# AC7842x register map
Vendor: AutoChips; Series: AC78; File version: 1.0
CPU: CM4 r0p1, little endian, MPU, FPU, VTOR, 4 interrupt priority bits
Registers are 32-bit, read-write, reset 0x0 unless marked. A register's access mark holds for its fields unless they carry their own. Offsets are from the block's base; [hi:lo] are bit positions; {n}, {i} and the like mark numbered series; 'fields as' and 'values as' point back to an identical list.

## SPM — System Power Manage
Base 0x40008000
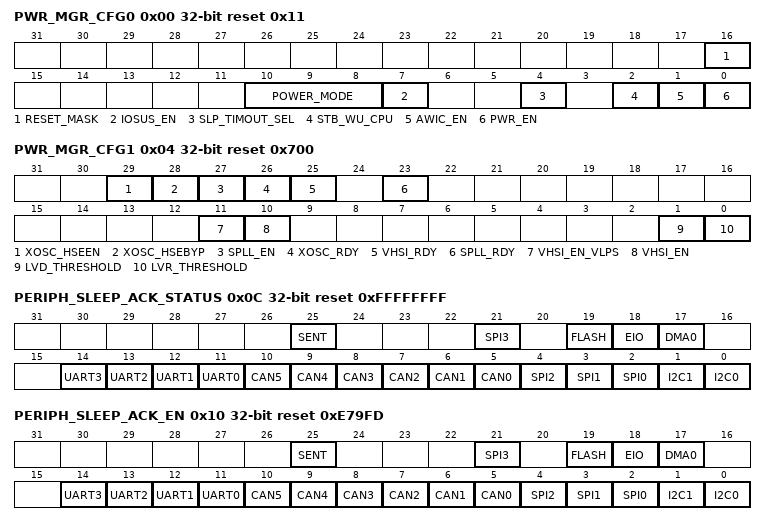
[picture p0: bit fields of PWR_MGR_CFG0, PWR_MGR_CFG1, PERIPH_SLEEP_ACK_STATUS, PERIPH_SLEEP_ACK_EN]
0x00 PWR_MGR_CFG0 reset 0x11 — Power Manage Config Register 0
  [16] RESET_MASK — Mask external reset in standby mode
    0=Disable; 1=Enable
  [10:8] POWER_MODE — Power Mode Control
    0=RUN Mode; 2=STOP1 Mode; 4=VLPS Mode; 5=Standby Mode
  [7] IOSUS_EN — IO suspend in low power mode
    0=Disable; 1=Enable
  [4] SLP_TIMOUT_SEL — Select SPM Interrupt/RESET When Occur ACK TimeOut
    0=Interrupt; 1=Reset
  [2] STB_WU_CPU — CPU continue run after standby wakeup
    0=Disable; 1=Enable
  [1] AWIC_EN — Enable AWIC Module
    0=Dsable; 1=Enable
  [0] PWR_EN — SPM Power Control Enable
    0=Disable; 1=Enable
0x04 PWR_MGR_CFG1 reset 0x700 — Power Manage Config Register 1
  [29] XOSC_HSEEN — Extern High-Speed Clock Enable
    0=Disable XOSC HSE; 1=Enable XOSC HSE
  [28] XOSC_HSEBYP — Extern High-Speed Clock Bypass
    0=Disable XOSC HSE Bypass; 1=Enable XOSC HSE Bypass
  [27] SPLL_EN — System PLL Enable
    0=Disable PLL; 1=Enable PLL
  [26] XOSC_RDY ro — XOSC Clock Ready Flag
    0=Not Ready; 1=Ready
  [25] VHSI_RDY ro — VHSI Ready Flag
    0=Not Ready; 1=Ready
  [23] SPLL_RDY ro — System PLL Ready Flag
    0=Not Ready; 1=Ready
  [11] VHSI_EN_VLPS — VHSI Enable in VLPS mode
    0=Disable; 1=Enable
  [10] VHSI_EN — VHSI Enable
    0=Disable; 1=Enable
  [1] LVD_THRESHOLD — LVD Voltage Threshold Set
    0=VLVDL=2.9V; 1=VLVDL=4.5V
  [0] LVR_THRESHOLD — LVR Voltage Threshold Set
    0=VLVRL=2.65V; 1=VLVRL=2.22V
0x0C PERIPH_SLEEP_ACK_STATUS ro reset 0xFFFFFFFF
  [25] SENT — SENT Sleep ACK Status
    0=No ACK; 1=ACK
  [21] SPI3 — SPI3 Sleep ACK Status
    0=No ACK; 1=ACK
  [19] FLASH — FLASH ACK Status
    0=NO ACK; 1=ACK
  [18] EIO — EIO Sleep ACK Status
    0=No ACK; 1=ACK
  [17] DMA0 — DMA0 Sleep ACK Status
    0=No ACK; 1=ACK
  [n+11] UART{n} (n=0..3) — UART{n} Sleep ACK Status
    0=No ACK; 1=ACK
  [n+5] CAN{n} (n=0..5) — CAN{n} Sleep ACK Status
    0=No ACK; 1=ACK
  [4] SPI2 — SPI2 Sleep ACK Status
    0=No ACK; 1=ACK
  [3] SPI1 — SPI1 Sleep ACK Status
    0=No ACK; 1=ACK
  [2] SPI0 — SPI0 Sleep ACK Status
    0=No ACK; 1=ACK
  [1] I2C1 — I2C1 Sleep ACK Status
    0=No ACK; 1=ACK
  [0] I2C0 — I2C0 Sleep ACK Status
    0=No ACK; 1=ACK
0x10 PERIPH_SLEEP_ACK_EN reset 0xE79FD — Periph Sleep Ack Enable Register
  [all] fields
    0=Disable; 1=Enable
  [25] SENT — SENT Sleep Ack Enable
  [21] SPI3 — SPI3 Sleep Ack Enable
  [19] FLASH — FLASH Sleep Idle Enable
  [18] EIO — EIO Sleep Ack Enable
  [17] DMA0 — DMA0 Sleep Ack Enable
  [n+11] UART{n} (n=0..3) — UART{n} Sleep Ack Enable
  [n+5] CAN{n} (n=0..5) — CAN{n} Sleep Ack Enable
  [4] SPI2 — SPI2 Sleep Ack Enable
  [3] SPI1 — SPI1 Sleep Ack Enable
  [2] SPI0 — SPI0 Sleep Ack Enable
  [1] I2C1 — I2C1 Sleep Ack Enable
  [0] I2C0 — I2C0 Sleep Ack Enable
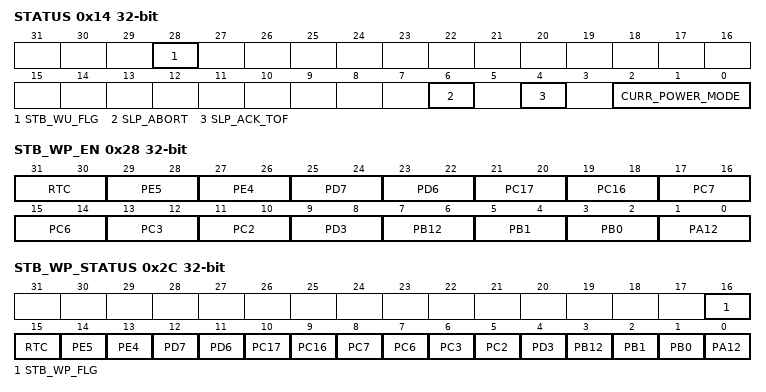
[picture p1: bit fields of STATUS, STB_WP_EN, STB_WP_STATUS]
0x14 STATUS
  [28] STB_WU_FLG — Standby wakeup interrupt flag
    0=Invalid; 1=Valid
  [6] SLP_ABORT — Sleep Abort Flag
    0=Invalid; 1=Valid
  [4] SLP_ACK_TOF — Peripheral Sleep Ack TimeOut Flag
    0=Invalid; 1=Valid
  [2:0] CURR_POWER_MODE ro — Display Current PowerMode
    0=RUN Mode; 2=STOP1 Mode; 4=VLPS Mode; 5=Standby Mode
0x28 STB_WP_EN — Standby Wakeup Enable Register
  [31:30] RTC — RTC Timeout Wakeup Enable
    0=Wakeup disable; 1=Rising edge wakeup enable; 3=Either edge wakeup enable
  [29:28] PE5 — PE5 Wakeup Enable
    0=Wakeup disable; 1=Rising edge wakeup enable; 2=Falling edge wakeup enable; 3=Either edge wakeup enable
  [27:26] PE4 — PE4 Wakeup Enable
    values as PE5
  [25:24] PD7 — PD7 Wakeup Enable
    values as PE5
  [23:22] PD6 — PD6 Wakeup Enable
    values as PE5
  [21:20] PC17 — PC17 Wakeup Enable
    values as PE5
  [19:18] PC16 — PC16 Wakeup Enable
    values as PE5
  [17:16] PC7 — PC7 Wakeup Enable
    values as PE5
  [15:14] PC6 — PC6 Wakeup Enable
    values as PE5
  [13:12] PC3 — PC3 Wakeup Enable
    values as PE5
  [11:10] PC2 — PC2 Wakeup Enable
    values as PE5
  [9:8] PD3 — PD3 Wakeup Enable
    values as PE5
  [7:6] PB12 — PB12 Wakeup Enable
    values as PE5
  [5:4] PB1 — PB1 Wakeup Enable
    values as PE5
  [3:2] PB0 — PB0 Wakeup Enable
    values as PE5
  [1:0] PA12 — PA12 Wakeup Enable
    values as PE5
0x2C STB_WP_STATUS — Standby Wakeup Status Register
  [all] fields
    0=Wakeup inactive; 1=Wakeup active
  [16] STB_WP_FLG — Standby Wakeup Flag
  [15] RTC — RTC Timeout Wakeup Flag
  [14] PE5 — PE5 Wakeup Flag
  [13] PE4 — PE4 Wakeup Flag
  [12] PD7 — PD7 Wakeup Flag
  [11] PD6 — PD6 Wakeup Flag
  [10] PC17 — PC17 Wakeup Flag
  [9] PC16 — PC16 Wakeup Flag
  [8] PC7 — PC7 Wakeup Flag
  [7] PC6 — PC6 Wakeup Flag
  [6] PC3 — PC3 Wakeup Flag
  [5] PC2 — PC2 Wakeup Flag
  [4] PD3 — PD3 Wakeup Flag
  [3] PB12 — PB12 Wakeup Flag
  [2] PB1 — PB1 Wakeup Flag
  [1] PB0 — PB0 Wakeup Flag
  [0] PA12 — PA12 Wakeup Flag
